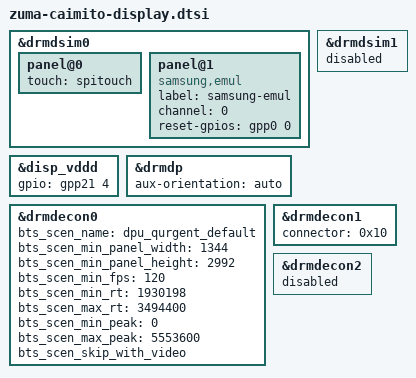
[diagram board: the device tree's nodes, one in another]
// SPDX-License-Identifier: GPL-2.0-only
/*
 * Display nodes for caimito boards.
 *
 * Copyright 2023 Google LLC
 *
 */

#include <dt-bindings/gpio/gpio.h>

&drmdsim0 {
	#address-cells = <1>;
	#size-cells = <0>;
	status = "okay";

	panel@0 {
		touch = <&spitouch>;
	};

	panel@1 {
		compatible = "samsung,emul";
		label = "samsung-emul";
		channel = <0>;

		/* reset, power */
		reset-gpios = <&gpp0 0 GPIO_ACTIVE_HIGH>;
	};
};

&drmdsim1 {
	#address-cells = <1>;
	#size-cells = <0>;
	/* If used, override it in product dtsi */
	status = "disabled";
};

&disp_vddd {
	status = "okay";
	gpio = <&gpp21 4 GPIO_ACTIVE_HIGH>;
};

&drmdp {
	status = "okay";
	aux-orientation = "auto";
};

&drmdecon0 {
	status = "okay";
	bts_scen_name = "dpu_qurgent_default";
	bts_scen_min_panel_width = <1344>;
	bts_scen_min_panel_height = <2992>;
	bts_scen_min_fps = <120>;
	bts_scen_min_rt = <1930198>;
	bts_scen_max_rt = <3494400>;
	bts_scen_min_peak = <0>;
	bts_scen_max_peak = <5553600>;
	bts_scen_skip_with_video;
};

&drmdecon1 {
	status = "okay";
	connector = <0x10>;
};

&drmdecon2 {
	status = "disabled";
};
